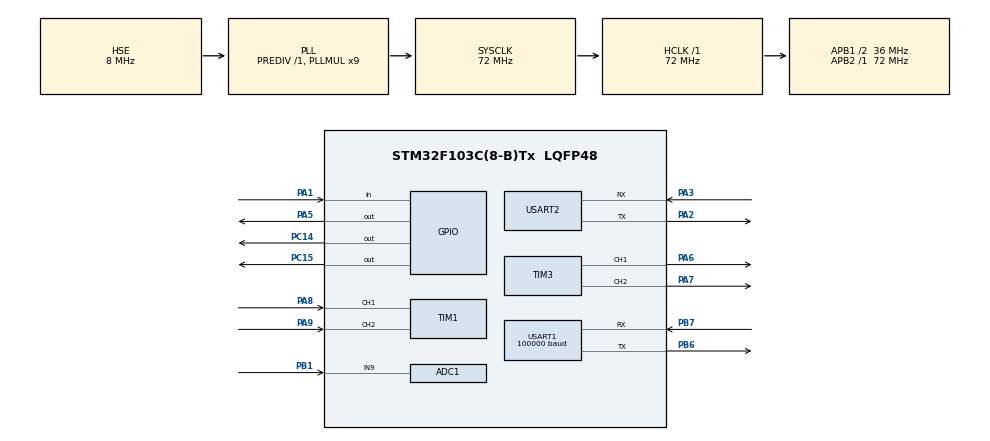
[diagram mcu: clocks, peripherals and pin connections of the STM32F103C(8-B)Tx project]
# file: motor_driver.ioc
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ADC1.Channel-2\#ChannelRegularConversion=ADC_CHANNEL_9
ADC1.ContinuousConvMode=DISABLE
ADC1.EnableInjectedConversion=DISABLE
ADC1.EnableRegularConversion=ENABLE
ADC1.ExternalTrigConv=ADC_EXTERNALTRIGCONV_T4_CC4
ADC1.ExternalTrigInjecConv=ADC_INJECTED_SOFTWARE_START
ADC1.InjNumberOfConversion=1
ADC1.NbrOfConversion=1
ADC1.NbrOfConversionFlag=1
ADC1.Rank-2\#ChannelRegularConversion=1
ADC1.SamplingTime-2\#ChannelRegularConversion=ADC_SAMPLETIME_1CYCLE_5
ADC1.master=1
Mcu.Family=STM32F1
Mcu.Name=STM32F103C(8-B)Tx
Mcu.Package=LQFP48
NVIC.ADC1_2_IRQn=true\:0\:0\:false\:false\:true\:true\:true\:true
NVIC.PriorityGroup=NVIC_PRIORITYGROUP_4
NVIC.TIM4_IRQn=true\:0\:0\:false\:false\:true\:true\:true\:true
NVIC.USART1_IRQn=true\:0\:0\:false\:false\:true\:true\:true\:true
NVIC.USART2_IRQn=true\:0\:0\:false\:false\:true\:true\:true\:true
PA1.Signal=GPIO_Input
PA13.Mode=Serial_Wire
PA13.Signal=SYS_JTMS-SWDIO
PA14.Mode=Serial_Wire
PA14.Signal=SYS_JTCK-SWCLK
PA2.Mode=Asynchronous
PA2.Signal=USART2_TX
PA3.Mode=Asynchronous
PA3.Signal=USART2_RX
PA5.Signal=GPIO_Output
PA6.Signal=S_TIM3_CH1
PA7.Signal=S_TIM3_CH2
PA8.Signal=S_TIM1_CH1
PA9.Signal=S_TIM1_CH2
PB1.Signal=ADCx_IN9
PB6.Mode=Asynchronous
PB6.Signal=USART1_TX
PB7.Mode=Asynchronous
PB7.Signal=USART1_RX
PC14-OSC32_IN.Signal=GPIO_Output
PC15-OSC32_OUT.Signal=GPIO_Output
PD0-OSC_IN.Mode=HSE-External-Oscillator
PD0-OSC_IN.Signal=RCC_OSC_IN
PD1-OSC_OUT.Mode=HSE-External-Oscillator
PD1-OSC_OUT.Signal=RCC_OSC_OUT
ProjectManager.HeapSize=0x200
ProjectManager.StackSize=0x400
ProjectManager.TargetToolchain=STM32CubeIDE
RCC.ADCPresc=RCC_ADCPCLK2_DIV6
RCC.AHBFreq_Value=72000000
RCC.APB1CLKDivider=RCC_HCLK_DIV2
RCC.APB1Freq_Value=36000000
RCC.APB1TimFreq_Value=72000000
RCC.APB2Freq_Value=72000000
RCC.APB2TimFreq_Value=72000000
RCC.HCLKFreq_Value=72000000
RCC.PLLMUL=RCC_PLL_MUL9
RCC.PLLSourceVirtual=RCC_PLLSOURCE_HSE
RCC.SYSCLKFreq_VALUE=72000000
RCC.SYSCLKSource=RCC_SYSCLKSOURCE_PLLCLK
RCC.USBFreq_Value=72000000
SH.ADCx_IN9.0=ADC1_IN9,IN9
SH.S_TIM1_CH1.0=TIM1_CH1,Encoder_Interface
SH.S_TIM1_CH2.0=TIM1_CH2,Encoder_Interface
SH.S_TIM3_CH1.0=TIM3_CH1,PWM Generation1 CH1
SH.S_TIM3_CH2.0=TIM3_CH2,PWM Generation2 CH2
TIM3.AutoReloadPreload=TIM_AUTORELOAD_PRELOAD_DISABLE
TIM3.Channel-PWM\ Generation1\ CH1=TIM_CHANNEL_1
TIM3.Channel-PWM\ Generation2\ CH2=TIM_CHANNEL_2
TIM3.Channel-PWM\ Generation4\ No\ Output=TIM_CHANNEL_4
TIM3.CounterMode=TIM_COUNTERMODE_CENTERALIGNED1
TIM3.Pulse-PWM\ Generation4\ No\ Output=65535
TIM3.TIM_MasterOutputTrigger=TIM_TRGO_OC4REF
TIM3.TIM_MasterSlaveMode=TIM_MASTERSLAVEMODE_DISABLE
TIM4.Period=1000
TIM4.Prescaler=719
USART1.BaudRate=100000
USART1.Parity=PARITY_EVEN
USART1.StopBits=STOPBITS_2
USART1.VirtualMode=VM_ASYNC
USART1.WordLength=WORDLENGTH_9B
USART2.VirtualMode=VM_ASYNC
VP_TIM3_VS_ClockSourceINT.Mode=Internal
VP_TIM3_VS_no_output4.Mode=PWM Generation4 No Output
VP_TIM4_VS_ClockSourceINT.Mode=Internal
board=custom

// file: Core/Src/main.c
/* USER CODE BEGIN Header */
/**
  ******************************************************************************
  * @file           : main.c
  * @brief          : Main program body
  ******************************************************************************
  * @attention
  *
  * Copyright (c) 2022 STMicroelectronics.
  * All rights reserved.
  *
  * This software is licensed under terms that can be found in the LICENSE file
  * in the root directory of this software component.
  * If no LICENSE file comes with this software, it is provided AS-IS.
  *
  ******************************************************************************
  */
/* USER CODE END Header */
#include "main.h"

/* USER CODE BEGIN Includes */
#include "user_main.hpp"

/* USER CODE END Includes */

 ADC_HandleTypeDef hadc1;

TIM_HandleTypeDef htim1;
TIM_HandleTypeDef htim3;
TIM_HandleTypeDef htim4;

UART_HandleTypeDef huart1;
UART_HandleTypeDef huart2;

void SystemClock_Config(void);
static void MX_GPIO_Init(void);
static void MX_USART2_UART_Init(void);
static void MX_TIM3_Init(void);
static void MX_TIM1_Init(void);
static void MX_USART1_UART_Init(void);
static void MX_TIM4_Init(void);
static void MX_ADC1_Init(void);

int main(void)
{

  /* MCU Configuration--------------------------------------------------------*/

  /* Reset of all peripherals, Initializes the Flash interface and the Systick. */
  HAL_Init();

  /* Configure the system clock */
  SystemClock_Config();

  /* Initialize all configured peripherals */
  MX_GPIO_Init();
  MX_USART2_UART_Init();
  MX_TIM3_Init();
  MX_TIM1_Init();
  MX_USART1_UART_Init();
  MX_TIM4_Init();
  MX_ADC1_Init();
  /* USER CODE BEGIN 2 */
  user_main();
  /* USER CODE END 2 */

  /* Infinite loop */
  while (1)
  {

  }
}

void SystemClock_Config(void)
{
  RCC_OscInitTypeDef RCC_OscInitStruct = {0};
  RCC_ClkInitTypeDef RCC_ClkInitStruct = {0};
  RCC_PeriphCLKInitTypeDef PeriphClkInit = {0};

  /** Initializes the RCC Oscillators according to the specified parameters
  * in the RCC_OscInitTypeDef structure.
  */
  RCC_OscInitStruct.OscillatorType = RCC_OSCILLATORTYPE_HSE;
  RCC_OscInitStruct.HSEState = RCC_HSE_ON;
  RCC_OscInitStruct.HSEPredivValue = RCC_HSE_PREDIV_DIV1;
  RCC_OscInitStruct.HSIState = RCC_HSI_ON;
  RCC_OscInitStruct.PLL.PLLState = RCC_PLL_ON;
  RCC_OscInitStruct.PLL.PLLSource = RCC_PLLSOURCE_HSE;
  RCC_OscInitStruct.PLL.PLLMUL = RCC_PLL_MUL9;
  if (HAL_RCC_OscConfig(&RCC_OscInitStruct) != HAL_OK)
  {
    Error_Handler();
  }

  /** Initializes the CPU, AHB and APB buses clocks
  */
  RCC_ClkInitStruct.ClockType = RCC_CLOCKTYPE_HCLK|RCC_CLOCKTYPE_SYSCLK
                              |RCC_CLOCKTYPE_PCLK1|RCC_CLOCKTYPE_PCLK2;
  RCC_ClkInitStruct.SYSCLKSource = RCC_SYSCLKSOURCE_PLLCLK;
  RCC_ClkInitStruct.AHBCLKDivider = RCC_SYSCLK_DIV1;
  RCC_ClkInitStruct.APB1CLKDivider = RCC_HCLK_DIV2;
  RCC_ClkInitStruct.APB2CLKDivider = RCC_HCLK_DIV1;

  if (HAL_RCC_ClockConfig(&RCC_ClkInitStruct, FLASH_LATENCY_2) != HAL_OK)
  {
    Error_Handler();
  }
  PeriphClkInit.PeriphClockSelection = RCC_PERIPHCLK_ADC;
  PeriphClkInit.AdcClockSelection = RCC_ADCPCLK2_DIV6;
  if (HAL_RCCEx_PeriphCLKConfig(&PeriphClkInit) != HAL_OK)
  {
    Error_Handler();
  }
}

static void MX_ADC1_Init(void)
{

  ADC_ChannelConfTypeDef sConfig = {0};

  /** Common config
  */
  hadc1.Instance = ADC1;
  hadc1.Init.ScanConvMode = ADC_SCAN_DISABLE;
  hadc1.Init.ContinuousConvMode = DISABLE;
  hadc1.Init.DiscontinuousConvMode = DISABLE;
  hadc1.Init.ExternalTrigConv = ADC_EXTERNALTRIGCONV_T4_CC4;
  hadc1.Init.DataAlign = ADC_DATAALIGN_RIGHT;
  hadc1.Init.NbrOfConversion = 1;
  if (HAL_ADC_Init(&hadc1) != HAL_OK)
  {
    Error_Handler();
  }

  /** Configure Regular Channel
  */
  sConfig.Channel = ADC_CHANNEL_9;
  sConfig.Rank = ADC_REGULAR_RANK_1;
  sConfig.SamplingTime = ADC_SAMPLETIME_1CYCLE_5;
  if (HAL_ADC_ConfigChannel(&hadc1, &sConfig) != HAL_OK)
  {
    Error_Handler();
  }

}

static void MX_TIM1_Init(void)
{

  TIM_Encoder_InitTypeDef sConfig = {0};
  TIM_MasterConfigTypeDef sMasterConfig = {0};

  htim1.Instance = TIM1;
  htim1.Init.Prescaler = 0;
  htim1.Init.CounterMode = TIM_COUNTERMODE_UP;
  htim1.Init.Period = 65535;
  htim1.Init.ClockDivision = TIM_CLOCKDIVISION_DIV1;
  htim1.Init.RepetitionCounter = 0;
  htim1.Init.AutoReloadPreload = TIM_AUTORELOAD_PRELOAD_DISABLE;
  sConfig.EncoderMode = TIM_ENCODERMODE_TI1;
  sConfig.IC1Polarity = TIM_ICPOLARITY_RISING;
  sConfig.IC1Selection = TIM_ICSELECTION_DIRECTTI;
  sConfig.IC1Prescaler = TIM_ICPSC_DIV1;
  sConfig.IC1Filter = 0;
  sConfig.IC2Polarity = TIM_ICPOLARITY_RISING;
  sConfig.IC2Selection = TIM_ICSELECTION_DIRECTTI;
  sConfig.IC2Prescaler = TIM_ICPSC_DIV1;
  sConfig.IC2Filter = 0;
  if (HAL_TIM_Encoder_Init(&htim1, &sConfig) != HAL_OK)
  {
    Error_Handler();
  }
  sMasterConfig.MasterOutputTrigger = TIM_TRGO_RESET;
  sMasterConfig.MasterSlaveMode = TIM_MASTERSLAVEMODE_DISABLE;
  if (HAL_TIMEx_MasterConfigSynchronization(&htim1, &sMasterConfig) != HAL_OK)
  {
    Error_Handler();
  }

}

static void MX_TIM3_Init(void)
{

  TIM_ClockConfigTypeDef sClockSourceConfig = {0};
  TIM_MasterConfigTypeDef sMasterConfig = {0};
  TIM_OC_InitTypeDef sConfigOC = {0};

  htim3.Instance = TIM3;
  htim3.Init.Prescaler = 0;
  htim3.Init.CounterMode = TIM_COUNTERMODE_CENTERALIGNED1;
  htim3.Init.Period = 65535;
  htim3.Init.ClockDivision = TIM_CLOCKDIVISION_DIV1;
  htim3.Init.AutoReloadPreload = TIM_AUTORELOAD_PRELOAD_DISABLE;
  if (HAL_TIM_Base_Init(&htim3) != HAL_OK)
  {
    Error_Handler();
  }
  sClockSourceConfig.ClockSource = TIM_CLOCKSOURCE_INTERNAL;
  if (HAL_TIM_ConfigClockSource(&htim3, &sClockSourceConfig) != HAL_OK)
  {
    Error_Handler();
  }
  if (HAL_TIM_PWM_Init(&htim3) != HAL_OK)
  {
    Error_Handler();
  }
  sMasterConfig.MasterOutputTrigger = TIM_TRGO_OC4REF;
  sMasterConfig.MasterSlaveMode = TIM_MASTERSLAVEMODE_DISABLE;
  if (HAL_TIMEx_MasterConfigSynchronization(&htim3, &sMasterConfig) != HAL_OK)
  {
    Error_Handler();
  }
  sConfigOC.OCMode = TIM_OCMODE_PWM1;
  sConfigOC.Pulse = 0;
  sConfigOC.OCPolarity = TIM_OCPOLARITY_HIGH;
  sConfigOC.OCFastMode = TIM_OCFAST_DISABLE;
  if (HAL_TIM_PWM_ConfigChannel(&htim3, &sConfigOC, TIM_CHANNEL_1) != HAL_OK)
  {
    Error_Handler();
  }
  if (HAL_TIM_PWM_ConfigChannel(&htim3, &sConfigOC, TIM_CHANNEL_2) != HAL_OK)
  {
    Error_Handler();
  }
  sConfigOC.Pulse = 65535;
  if (HAL_TIM_PWM_ConfigChannel(&htim3, &sConfigOC, TIM_CHANNEL_4) != HAL_OK)
  {
    Error_Handler();
  }
  HAL_TIM_MspPostInit(&htim3);

}

static void MX_TIM4_Init(void)
{

  TIM_ClockConfigTypeDef sClockSourceConfig = {0};
  TIM_MasterConfigTypeDef sMasterConfig = {0};

  htim4.Instance = TIM4;
  htim4.Init.Prescaler = 719;
  htim4.Init.CounterMode = TIM_COUNTERMODE_UP;
  htim4.Init.Period = 1000;
  htim4.Init.ClockDivision = TIM_CLOCKDIVISION_DIV1;
  htim4.Init.AutoReloadPreload = TIM_AUTORELOAD_PRELOAD_DISABLE;
  if (HAL_TIM_Base_Init(&htim4) != HAL_OK)
  {
    Error_Handler();
  }
  sClockSourceConfig.ClockSource = TIM_CLOCKSOURCE_INTERNAL;
  if (HAL_TIM_ConfigClockSource(&htim4, &sClockSourceConfig) != HAL_OK)
  {
    Error_Handler();
  }
  sMasterConfig.MasterOutputTrigger = TIM_TRGO_RESET;
  sMasterConfig.MasterSlaveMode = TIM_MASTERSLAVEMODE_DISABLE;
  if (HAL_TIMEx_MasterConfigSynchronization(&htim4, &sMasterConfig) != HAL_OK)
  {
    Error_Handler();
  }

}

static void MX_USART1_UART_Init(void)
{

  huart1.Instance = USART1;
  huart1.Init.BaudRate = 100000;
  huart1.Init.WordLength = UART_WORDLENGTH_9B;
  huart1.Init.StopBits = UART_STOPBITS_2;
  huart1.Init.Parity = UART_PARITY_EVEN;
  huart1.Init.Mode = UART_MODE_TX_RX;
  huart1.Init.HwFlowCtl = UART_HWCONTROL_NONE;
  huart1.Init.OverSampling = UART_OVERSAMPLING_16;
  if (HAL_UART_Init(&huart1) != HAL_OK)
  {
    Error_Handler();
  }

}

static void MX_USART2_UART_Init(void)
{

  huart2.Instance = USART2;
  huart2.Init.BaudRate = 115200;
  huart2.Init.WordLength = UART_WORDLENGTH_8B;
  huart2.Init.StopBits = UART_STOPBITS_1;
  huart2.Init.Parity = UART_PARITY_NONE;
  huart2.Init.Mode = UART_MODE_TX_RX;
  huart2.Init.HwFlowCtl = UART_HWCONTROL_NONE;
  huart2.Init.OverSampling = UART_OVERSAMPLING_16;
  if (HAL_UART_Init(&huart2) != HAL_OK)
  {
    Error_Handler();
  }

}

static void MX_GPIO_Init(void)
{
  GPIO_InitTypeDef GPIO_InitStruct = {0};

  /* GPIO Ports Clock Enable */
  __HAL_RCC_GPIOC_CLK_ENABLE();
  __HAL_RCC_GPIOD_CLK_ENABLE();
  __HAL_RCC_GPIOA_CLK_ENABLE();
  __HAL_RCC_GPIOB_CLK_ENABLE();

  /*Configure GPIO pin Output Level */
  HAL_GPIO_WritePin(GPIOC, GPIO_PIN_14|GPIO_PIN_15, GPIO_PIN_RESET);

  /*Configure GPIO pin Output Level */
  HAL_GPIO_WritePin(GPIOA, GPIO_PIN_5, GPIO_PIN_RESET);

  /*Configure GPIO pins : PC14 PC15 */
  GPIO_InitStruct.Pin = GPIO_PIN_14|GPIO_PIN_15;
  GPIO_InitStruct.Mode = GPIO_MODE_OUTPUT_PP;
  GPIO_InitStruct.Pull = GPIO_NOPULL;
  GPIO_InitStruct.Speed = GPIO_SPEED_FREQ_LOW;
  HAL_GPIO_Init(GPIOC, &GPIO_InitStruct);

  /*Configure GPIO pin : PA1 */
  GPIO_InitStruct.Pin = GPIO_PIN_1;
  GPIO_InitStruct.Mode = GPIO_MODE_INPUT;
  GPIO_InitStruct.Pull = GPIO_NOPULL;
  HAL_GPIO_Init(GPIOA, &GPIO_InitStruct);

  /*Configure GPIO pin : PA5 */
  GPIO_InitStruct.Pin = GPIO_PIN_5;
  GPIO_InitStruct.Mode = GPIO_MODE_OUTPUT_PP;
  GPIO_InitStruct.Pull = GPIO_NOPULL;
  GPIO_InitStruct.Speed = GPIO_SPEED_FREQ_LOW;
  HAL_GPIO_Init(GPIOA, &GPIO_InitStruct);

}

void Error_Handler(void)
{
  __disable_irq();
  while (1)
  {
  }
}
